# MMCSD8_MMC_CTLCFG_0FA00000h register map
Vendor: Texas Instruments
Registers are 16-bit, read-write, reset 0x0 unless marked. A register's access mark holds for its fields unless they carry their own. Offsets are as the file gives them; [hi:lo] are bit positions; {n}, {i} and the like mark numbered series.

## mmc_ctlcfg (part 2 of 4)
0x00 MMC_CTLCFG_SDMA_SYS_ADDR_LO — This register contains the Lower 16-bit of physical system memory address used for DMA transfers or the second argument for the Auto CMD23 in Host version 3.0 and as 32-bit Block Count in Version 4.10.
  [15:0] SDMA_ADDRESS — When Host Version 4 Enable is set to 0 in the Host Control 2 register,DMA uses this register as system address in only 32-bit addressing mode. Auto CMD23 cannot be used with SDMA. When Host Version 4 Enable is set to 1, SDMA uses ADMA System Address register [05Fh-058h] instead of using this register to sup- port both 32-bit and 64-bit addressing. This register is re-assigned to 32-bit Block Count and then SDMA may use Auto CMD23.[1] SDMA System Address [Host Version 4 Enable = 0] This register contains the system memory address for a SDMA transfer in 32-bit addressing mode. When the Host Controller stops a SDMA transfer, this register shall point to the system address of the next contiguous data position. It can be accessed only if no transaction is executing [i.e., after a transaction has stopped]. Reading this register during SDMA transfers may return an invalid value. The Host Driver shall initialize this register before starting a SDMA transaction. After SDMA has stopped, the next system address of the next contiguous data posi- tion can be read from this register. The SDMA transfer waits at the every boundary specified by the SDMA Buffer Boundary in the Block Size register. The Host Controller generates DMA Interrupt to request the Host Driver to update this register. The Host Driver sets the next system address of the next data position to this register. When the most upper byte of this register [003h] is written, the Host Controller restarts the SDMA transfer. When restarting SDMA by setting Continue Request in the Block Gap Control register, the Host Controller shall start at the next contiguous address stored here in the SDMA System Address register. ADMA does not use this register. [2] 32-bit Block Count [Host Version 4 Enable = 1] Host Controller Version 4.10 re-defines this register as 32-bit Block Count [Refer to Section 1.15 for more details about block count extension]. In version 4.00, this register may be used as 32-bit block count only for Auto CMD23 to set the argument of the CMD23 while executing Auto CMD23. The Host Controller would decrement the block count of this register every block transfer and data transfer stops when the count reaches zero. This register should be accessed only when no transaction is executing. Reading this register during data transfers may return invalid value. Reset Source: vbus_amod_g_rst_n
0x02 MMC_CTLCFG_SDMA_SYS_ADDR_HI — This register contains the Upper 16-bit of physical system memory address used for DMA transfers or the second argument for the Auto CMD23 in Host version 3.0 and as 32-bit Block Count in Version 4.10.
  [15:0] SDMA_ADDRESS — This register contains the Upper 16-bit of physical system memory address used for DMA transfers or the second argument for the Auto CMD23 in Host version 3.0 and as 32-bit Block Count in Version 4.10. Reset Source: vbus_amod_g_rst_n
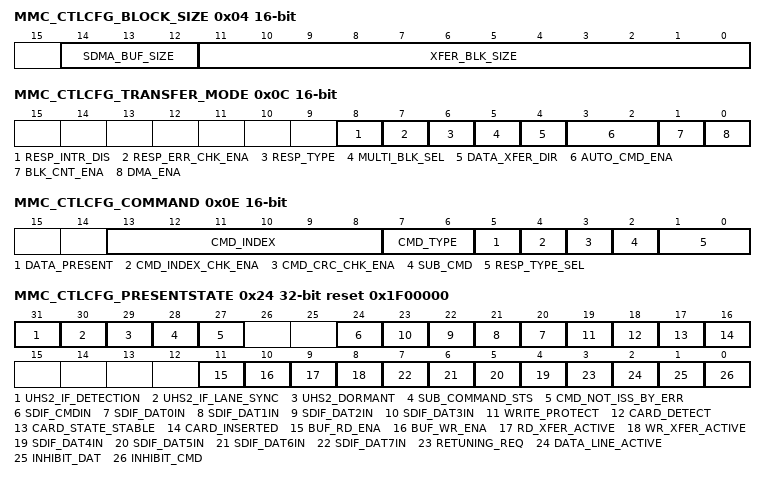
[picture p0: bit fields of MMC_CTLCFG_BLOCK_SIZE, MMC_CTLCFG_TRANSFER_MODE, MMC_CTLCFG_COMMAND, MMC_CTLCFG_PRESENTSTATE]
0x04 MMC_CTLCFG_BLOCK_SIZE — This register is used to configure the number of bytes in a data block
  [14:12] SDMA_BUF_SIZE — To perform long DMA transfer, System Address register shall be updated at every system boundary during DMA transfer. These bits specify the size of contiguous buffer in the system memory. The DMA transfer shall wait at the every boundary specified by these fields and the HC generates the DMA Interrupt to request the HD to update the System Address register.These bits shall support when the DMA Support in the Capabilities register is set to 1 and this function is active when the DMA Enable in the Transfer Mode register is set to 1. 0 4KB1 8KB2 16KB3 32KB4 64KB5 128KB6 256KB7 512KB
  [11:0] XFER_BLK_SIZE — This field specifies the block size for block data transfers for CMD17, CMD18, CMD24, CMD25 and CMD53. It can be accessed only if no transaction is executing [i.e after a transaction has stopped]. Read operations during transfer return an invalid value and write operations shall be ignored. 0 No data transfer1 1 Byte2 2 Bytes512 512 Bytes2048 2048 Bytes
0x06 MMC_CTLCFG_BLOCK_COUNT — This register is used to configure the number of data blocks
  [15:0] XFER_BLK_CNT — Host Controller Version 4.10 extends block count to 32-bit [Refer to Section 1.15].Selection of either 16-bit Block Count register or 32-bit Block Count register is defined as follows: [1] If Host Version 4 Enable in the Host Control 2 register is set to 0 or 16-bit Block Count register is set to non-zero, 16-bit Block Count register is selected [2] If Host Version 4 Enable is set to 1 and 16-bit Block Count register is set to zero, 32-bit Block Count register is selected.Use of 16-bit/32-bit Block Count register is enabled when Block Count Enable in the Transfer Mode register is set to 1 and is valid only for multiple block transfers. The Host Driver shall set this register to a value between 1 and the maximum block count.The Host Controller decrements the block count after each block transfer and stops when the count reaches zero. Setting the block count to 0 results in no data blocks is transferred.This register should be accessed only when no transaction is executing [i.e., after transactions arestopped]. During data transfer,read operations on this register may return an invalid value andwrite operations are ignored. 0 Stop count1 1 block2 2 blocks3 3 blocks65535 65535 blocks
0x08 MMC_CTLCFG_ARGUMENT1_LO — This register contains Lower bits of SD Command Argument
  [15:0] CMD_ARG1 — The SD Command Argument is specified as bit23-8 of Command-Format. Reset Source: vbus_amod_g_rst_n
0x0A MMC_CTLCFG_ARGUMENT1_HI — This register contains higher bits of SD Command Argument
  [15:0] CMD_ARG1 — The SD Command Argument is specified as bit39-24 of Command-Format. Reset Source: vbus_amod_g_rst_n
0x0C MMC_CTLCFG_TRANSFER_MODE — This register is used to control the operations of data transfers
  [8] RESP_INTR_DIS — Host Controller Version 4.00 supports response error check function to avoid overhead of response error check by Host Driver. Only R1 or R5 can be checked. If Host Driver checks response error,setsthis bit to 0 and waits Command Complete Interrupt and then checks the response register. If Host Controller checks response error, sets this bit to 1 and sets Response Error Check Enable to 1. Command Complete Interrupt is disabled by this bit regardless of Command Complete Signal Enable. 0 Enable Response Interrupt1 Disable Response Interrupt
  [7] RESP_ERR_CHK_ENA — Host Controller Version 4.00 supports response error check function to avoid overhead of response error check by Host Driver. Only R1 or R5 can be checked.If Host Driver checks response error, this bit is set to 0 and Response Interrupt Disable is set to 0.If Host Controller checks response error, sets this bit to 1 and sets Response Interrupt Disable to 1. Response Type R1 / R5 selects either R1 or R5 response type. If an error is detected, Response Error Interrupt is generated in the Response Error Interrupt Status register. 0 Disable Response Error Check1 Enable Response Error Check
  [6] RESP_TYPE — When response error check is enabled, this bit selects either R1 or R5 response types. Two types of response checks are supported: R1 for memory and R5 for SDIO. Error Statuses Checked in R1 .Bit31 OUT_OF_RANGE .Bit30 ADDRESS_ERROR .Bit29 BLOCK_LEN_ERROR .Bit26 WP_VIOLATION .Bit25 CARD_IS_LOCKED .Bit23 COM_CRC_ERROR .Bit21 CARD_ECC_FAILED .Bit20 CC_ERROR .Bit19 ERROR Response Flags Checked in R5 .Bit07 COM_CRC_ERROR .Bit03 ERROR .Bit01 FUNCTION_NUMBER .Bit00 OUT_OF_RANGE 0 Memory1 SDIO
  [5] MULTI_BLK_SEL — This bit enables multiple block data transfers. 0 Single Block transfer1 Multiple Block transfer
  [4] DATA_XFER_DIR — This bit defines the direction of data transfers. 0 Write from Host to Card1 Read from Card to Host
  [3:2] AUTO_CMD_ENA — There are three methods to stop Multiple-block read and write operation. [1] Auto CMD12 Enable: Multiple-block read and write commands for memory require CMD12 to stop the operation. When this field is set to 01b, the Host Controller issues CMD12 automatically when last block transfer is completed. Auto CMD12 error is indicated to the Auto CMD Error Status register. The Host Driver shall not set this bit if the command does not require CMD12. When Host Version 4 Enable =0, CMD12 is issued when 16-bit Block Count is expired. When Host Version 4 Enable =1, CMD12 is issued when 16-bit Block Count or 32-bit Block Count is expired. [2] Auto CMD23 Enable: When this bit field is set to 10b, the Host Controller issues a CMD23 automatically before issuing a command specified in the Command register. The Host Controller Version 3.00 and later shall support this function. The following conditions are required to use the Auto CMD23. The following conditions are required to use the Auto CMD23. Auto CMD23 Supported [Host Controller Version is 3.00 or later]. A memory card that supports CMD23 [SCR[33]=1]. If DMA is used, it shall be ADMA. Only when CMD18 or CMD25 is issued. Auto CMD23 can be used with or without ADMA. By Writing the Command register, the Host Controller issues a CMD23 first and then issues a command specified by the Command Index in Com-mand register. If response errors of CMD23 are detected, the second command is not issued. A CMD23 error is indicated in the Auto CMD Error Status register.32-bit block count value for CMD23 is set to 32-bit Block Count [SDMA System Address] register. [3] Auto CMD Auto Select [Version 4.10] As CMD23 is optional for SD memory card except UHS 104 card, if card supports CMD23, Auto CMD 23 should be used instead of Auto CMD12. Host Controller Version 4.10 defines this Auto CMD Auto Select mode. Selection of Auto CMD depends on setting of CMD23 Enable in the Host Control 2 register which indicates whether card supports CMD23. If CMD23 Enable =1, Auto CMD23 is used and if CMD23 Enable =0, Auto CMD12 is used. In case of Version 4.10 or later, use of Auto CMD Auto Select is recommended rather than use of Auto CMD12 Enable or Auto CMD23 Enable. 0 Auto CMD Disable1 Auto CMD12 Enable2 Auto CMD23 Enable3 Auto CMD Auto Select
  [1] BLK_CNT_ENA — This bit is used to enable the Block count register, which is only relevant for multiple block transfers. When this bit is 0, the Block Count register is disabled, which is useful in executing an infinite transfer. 0 Disable Block count1 Enable Block count
  [0] DMA_ENA — DMA can be enabled only if DMA Support bit in the Capabilities register is set. If this bit is set to 1, a DMA operation shall begin when the HD writes to the upper byte of Command register [00Fh]. 0 DMA mode is Disabled1 DMA mode is Enabled
0x0E MMC_CTLCFG_COMMAND — This register is used to program the Command for host controller
  [13:8] CMD_INDEX — This bit shall be set to the command number [CMD0-63, ACMD0-63]. Reset Source: vbus_amod_g_rst_n
  [7:6] CMD_TYPE — There are three types of special commands. Suspend, Resume andAbort. These bits shall bet set to 00b for all other commands. Suspend Command:If the Suspend command succeeds, the HC shall assume the SD Bus has been released and that it is possible to issue the next command which uses the DAT line. The HC shall de-assert Read Wait for read transactions and stop checking busy for write transactions. The Interrupt cycle shall start, in 4-bit mode. If the Suspend command fails, the HC shall maintain its current state. and the HD shall restart the transfer by setting Continue Request in the Block Gap Control Register. Resume Command:The HD re-starts the data transfer by restoring the registers in the range of 000-00Dh. The HC shall check for busy before starting write transfers. Abort Command:If this command is set when exe- cuting a read transfer, the HC shall stop reads to the buffer. If this command is set when executing a writetransfer, the HC shall stop driving the DAT line. After issuing the Abort command, the HD should issue a software reset. 0 Normal1 Suspend2 Resume3 Abort
  [5] DATA_PRESENT — This bit is set to 1 to indicate that data is present and shall be transferred using the DAT line. If is set to 0 for the following: 1. Commands using only CMD line [ex. CMD52]. 2. Commands with no data transferbut using busy signal on DAT[0]line [R1b or R5b ex. CMD38]. 3. Resume Command. 0 Data not Present1 Data present
  [4] CMD_INDEX_CHK_ENA — If this bit is set to 1, the HC shall check the index field in the response to see if it has the same value as the command index. If it is not, it is reported as a Command Index Error. If this bit is set to 0, the Index field is not checked. 0 Disable Command Index Check1 Enable Command Index Check
  [3] CMD_CRC_CHK_ENA — If this bit is set to 1, the HC shall check the CRC field in the response. If an error is detected, it is reported as a Command CRC Error. If this bit is set to 0, the CRC field is not checked. 0 Disable Command CRC Check1 Enable Command CRC Check
  [2] SUB_CMD — This bit is added from Version 4.10 to distinguish a main command or sub command [Refer to Section 1.17]. When issuing a main com-mand, this bit is set to 0 and when issuing a sub command, this bit is set to 1. Setting of this bit is checked by Sub Command Status in the Present State register.Host Driver manages whether main or sub command. Host Controller does not refer to this bit to issue a command. 0 Main Command1 Sub Command
  [1:0] RESP_TYPE_SEL — Response Type Select. 0 No Response1 Response length 1362 Response length 483 Response length 48 check Busy after response
0x10 MMC_CTLCFG_RESPONSE_j ro — This register is used to store responses from SD Cards
  [15:0] CMD_RESP — R[] refers to a bit range within the response data as transmitted on the SD Bus, REP[] refers to a bit range within the Response register. Reset Source: vbus_amod_g_rst_n
0x20 MMC_CTLCFG_DATA_PORT 32-bit — This register is used to access internal buffer
  [31:0] BUF_RD_DATA — The Host Controller Buffer can be accessed through this 32-bit Data Port Register. Reset Source: vbus_amod_g_rst_n
0x24 MMC_CTLCFG_PRESENTSTATE 32-bit ro reset 0x1F00000 — The Host Driver can get status of the Host Controller from this 32-bit read-only register
  [31] UHS2_IF_DETECTION — This status indicates whether a card supports UHS-II IF. This status is enabled by setting UHS-II Interface Enable to 1 in the Host Control 2 regis-ter. UHS-II interface initialization is activated by setting SD Clock Enable in the Clock Control reg-ister. Host Controller drives STB.L on D0 lanefrom EIDL state and waits for receiving STB.L on D1 lane. This bit is set to 1 if STB.L is detected on D1 lane. Host Controller shall compensate latency from setting SD Clock Enable to output STB.L on D0 lane when Reading this status [Refer to Figure 3-35 about details of this method]. This bit may be read any time after setting SD Clock Enable for faster UHS-II IF detection but Host Driver shall check this status at least 200us period from set- ting SD Clock Enable until detecting UHS-II IF. After UHS-II IF is detected, this bit is cleared by when EIDL is detected on D0 lane, UHS-II Inter-face Enable is set to 0 or Host full reset is exe-cuted. '0' UHS-II IF is not detected '1' UHS-II IF is detected Reset Source: vbus_amod_g_rst_n
  [30] UHS2_IF_LANE_SYNC — This status indicates whether lane is synchronized in UHS-II mode. This status is enabled by setting UHS-II Interface Enable to 1 in the Host Control 2 register. On detecting UHS-II Interface [D31=1], Host Controller provides SYN LSS on D0 lane and waits for receiving SYN LSS on D1 lane. If SYN LSS is detected on D1 lane, Host Controller pro-vides LIDL LSS on D0 lane and waits for receiving LIDL LSS on D1 lane.In case of Version 4.00, this bit indicates comple-tion of Device PHY Initialization by detecting LIDL LSS on D1 lane.From Version 4.10, Host Controller may imple-ment a specific PHY verification method and PHYInitialization Failure can be indicated by keeping this bit to 0 even LIDL LSS is detected on D1 lane.Host Driver detects PHY Initialization Failure by timeout.This bit is cleared by when D0 lane is set to EIDL,UHS-II Interface Enable is set to 0 or executes Host full reset. 0 UHS-II PHY is not initialized1 UHS-II PHY is initialized
  [29] UHS2_DORMANT — This status indicates whether UHS-II Ianes enterDormant state. This function is enabled by setting UHS-II Interface Enable to 1 in the Host Control 2 register. On issuing GO_DORMAT_STATE com-mand, Go Dormant Command [111b]; is set to Command type in the UHS-II Command register.This command type acts as a trigger to enterlanes into dormant state. Host Controller provides STB.H and EIDL on D0 lane and waits for receiv-ing STB.H and EIDL on D1 lane. This bit is set to 1 after the time of T_DMT_ENTRY [750 RCLK cycle] or more from detecting EIDL on D1 lane. RCLK may be stopped in dormant state, by setting SD Clock Enable to 0 in the Clock Control register while In Dormant State bit is set to 1. On WritingClock Control register with setting SD Clock Enable to 1, Host Controller wakes lanes to exit Dormant State and In Dormant State is set to 0. In case of the card enters Hibernate Mode [RCLK is stopped], Host Driver may turn off VDD1 by clearing SD Bus Power for VDD1 bit in the Power Control register. Host Controller shall turn off VDD1 after stopping RCLK. This bit is cleared by when Host Controller drives STB.L on D0 lane, UHS-II Interface Enable is set to 0 or executesHost full reset. 0 Not in DORMANT state1 In DORMANT state
  [28] SUB_COMMAND_STS — The Command register and Response register are commonly used for main command and sub command. This status is used to distinguish which response error statuses, main command or sub command, indicated in the Error Interrupt Status register or in the UHS-II Error Interrupt Status register. Refer to Section 1.17 about details of response error statuses. Just before Reading of this register, the Sub Command Flag of the Command register or the UHS-II Command register is copied to this status. This status is effective not only when Response Error interrupt is generated but also when data error interrupt is generated with Command Not Issued by Error [D27 of this register] or Auto CMD Error interrupt is generated with Command Not Issued by Error by Auto CMD12 in the Auto CMD Error Status register. 1 - Sub Command Status 0 - Main Command Status Reset Source: vbus_amod_g_rst_n
  [27] CMD_NOT_ISS_BY_ERR — Setting of this status indicates that a command cannot be issued due to an error except Auto CMD12 error. [Equivalent error status by Auto CMD12 error is defined as Command Not Issued By Auto CMD12 Error in the Auto CMD Error Status register.] This status is set to 1 when Host Controller cannot issue a command after setting Command register or UHS-II Command register.Refer to Section 3.10 about 2L-HD error case inUHS-II mode.Sub Command Status [D28] indicates which command is not issued [main or sub]. 1 - Command cannot be issued 0 - No error for issuing a command Reset Source: vbus_amod_g_rst_n
  [24] SDIF_CMDIN — This status is used to check DAT line level to recover from errors, and for debugging. Reset Source: vbus_amod_g_rst_n
  [n+20] SDIF_DAT{n}IN (n=0..3) — This status is used to check DAT line level to recover from errors, and for debugging. This is especially useful in detecting the busy signal level from DAT[{n}]. Reset Source: vbus_amod_g_rst_n
  [19] WRITE_PROTECT — The Write Protect Switch is supported for memory and combo cards.This bit reflects the SDWP# pin. 0 Write protected (SDWP# = 1)1 Write enabled (SDWP# = 0)
  [18] CARD_DETECT — This bit reflects the inverse value of the SDCD# pin. '0' No Card present [SDCD# = 1] '1' Card present [SDCD# = 0] Reset Source: vbus_amod_g_rst_n
  [17] CARD_STATE_STABLE — This bit is used for testing. If it is 0, the Card Detect Pin Level is not stable. If this bit is set to 1,it means the Card Detect Pin Level is stable. The Software Reset For All in the Software Reset Register shall not affect this bit. '0' Reset of Debouncing '1' No Card or Inserted Reset Source: vbus_amod_g_rst_n
  [16] CARD_INSERTED — This bit indicates whether a card has been inserted. Changing from 0 to 1 generates a Card Insertion interrupt in the Normal Interrupt Status register and changing from 1 to 0 generates a Card Removal Interrupt in the Normal Interrupt Status register. The Software Reset For All in the Software Reset register shall not affect this bit.If a Card is removed while its power is on and its clock is oscillating, the HC shall clear SD Bus Power in the Power Control register and SD Clock Enable in the Clock control register. In addition the HD should clear the HC by the Software Reset For All in Software register. The card detect is active regardless of the SD Bus Power. '0' Reset or Debouncing or No Card '1' Card Inserted Reset Source: vbus_amod_g_rst_n
  [11] BUF_RD_ENA — This status is used for non-DMA read transfers.This read only flag indicates that valid data exists in the host side buffer status. If this bit is 1, readable data exists in the buffer. A change of this bit from 1 to 0 occurs when all the block data is read from the buffer. A change of this bit from 0 to 1 occurs when all the block data is ready in the buffer and generates the Buffer Read Ready Interrupt. 0 Read Disable1 Read Enable
  [10] BUF_WR_ENA — This status is used for non-DMA write transfers.This read only flag indicates if space is available for write data. If this bit is 1, data can be written to the buffer. A change of this bit from 1 to 0 occurs when all the block data is written to the buffer. A change of this bit from 0 to 1 occurs when top of block data can be written to the buffer and generates the Buffer Write Ready Interrupt. 0 Write Disable1 Write Enable
  [9] RD_XFER_ACTIVE — This status is used for detecting completion of a read transfer. This bit is set to 1 for either of the following conditions: After the end bit of the read command. When Writing a 1 to continue Request in the Block Gap Control register to restart a read transfer. This bit is cleared to 0 for either of the following conditions: When the last data block as specified by block length is transferred to the system. When all valid data blocks have been transferred to the system and no current block transfers are being sent as a result of the Stop At Block Gap Request set to 1. A transfer complete interrupt is generated when this bit changes to 0. '0' No valid data '1' Transferring data 0 No valid data1 Transferring data
  [8] WR_XFER_ACTIVE — This status indicates a write transfer is active. If this bit is 0, it means no valid write data exists in the HC. This bit is set in either of the following cases: After the end bit of the write command. When Writing a 1 to Continue Request in the Block Gap Control register to restart a write transfer. This bit is cleared in either of the following cases: After getting the CRC status of the last data block as specified by the transfer count [Single or Multiple] After getting a CRC status of any block where data transmission is about to be stopped by a Stop At Block Gap Request.During a write transaction, a Block Gap Event interrupt is generated when this bit is changed to 0, as a result of the Stop At Block Gap Request being set. This status is useful for the HD in determining when to issue commands during write busy. 0 No valid data1 Transferring data
  [n] SDIF_DAT{n}IN (n=4..7) — This status is used to check DAT line level to recover from errors, and for debugging. Reset Source: vbus_amod_g_rst_n
  [3] RETUNING_REQ — Host Controller may request Host Driver to execute re-tuning sequence by setting this bit when the data window is shifted by temperature drift and a tuned sampling point does not have a good margin to receive correct data.This bit is cleared when a command is issued with setting Execute Tuning in the Host Control 2 register. Changing of this bit from 0 to 1 generates Re-Tuning Event. Refer to Normal Interrupt registers for more detail. This bit isn't set to 1 if Sampling Clock Select in the Host Control 2 register is set to 0 [using fixed sampling clock]. 0 Fixed or well tuned sampling clock1 Sampling clock needs re-tuning
  [2] DATA_LINE_ACTIVE — This bit indicates whether one of the DAT line on SD bus is in use. 0 DAT line inactive1 DAT line active
  [1] INHIBIT_DAT — This status bit is generated if either the DAT Line Active or the Read transfer Active is set to 1. If this bit is 0, it indicates the HC can issue the next SD command. Commands with busy signal belong to Command Inhibit [DAT] [ex. R1b, R5b type].Changing from 1 to 0 generates a Transfer Complete interrupt in the Normal interrupt status register.Note: The SD Host Driver can save registers in the range of 000-00Dh for a suspend transaction after this bit has changed from 1 to 0. '0' Can issue command which uses the DAT line '1' Cannot issue command which uses the DATline Reset Source: vbus_amod_g_rst_n
  [0] INHIBIT_CMD — SD ModeIf this bit is 0, it indicates the CMD line is not in use and the HC can issue a SD command using the CMD line. This bit is set immediately after the Command register [00Fh] is written. This bit is cleared when the command response is received. Even if the Command Inhibit [DAT] is set to 1, Commands using only the CMD line can be issued if this bit is 0. Changing from 1 to 0 gener- ates a Command complete interrupt in the Normal Interrupt Status register. If the HC cannot issuethe command because of a command conflict error or because of Command Not Issued By Auto CMD12 Error, this bit shall remain 1 and the Com- mand Complete is not set. Status issuing Auto CMD12 is not read from this bit.Auto CMD12 and Auto CMD23 consist of two responses. In this case, this bit is not cleared by the response of CMD12 or CMD23 but cleared by the response of a read/write command. Status issuing Auto CMD12 is not read from this bit. So ifa command is issued during Auto CMD12 opera- tion, Host Controller shall manage to issue two commands: CMD12 and a command set by Com-mand register. UHS-II ModeThis bit is 0 means that a command packet can be issued by the Host Controller. While this bit is set to 1, which means the Host Controller is not ready to issue a next command, Host Driver shall not write the registers from UHS-II BlockSize [Offset 080h] to the UHS-II Command [Offset 09Eh]. Changing from 1 to 0 generates a Command Complete Interrupt in the Normal Interrupt Status-register. 1- Host Controller is not ready to issue a com-mand 0 - Host Controller is ready to issue a commandVersion 4.10 adds a new control to prevent error statuses from overWriting by receipt of a next com-mand. This status keeps indicating 1 while any of response error statuses is set to 1 [as described in Section 1.17], Command Not Issued by Error in this register is set to 1 or Command Not Issued by Auto CMD12 Error in the Auto CMD Error Status register is set to 1. Software Reset For CMD Lineis used to clear the error statuses above and this status. Reset Source: vbus_amod_g_rst_n
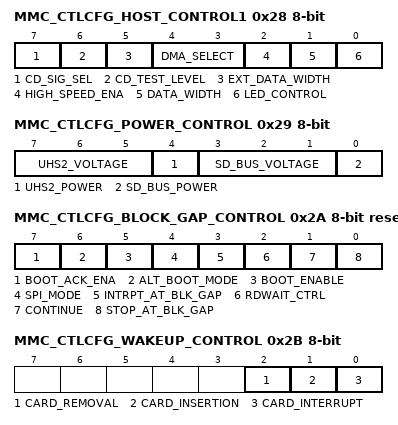
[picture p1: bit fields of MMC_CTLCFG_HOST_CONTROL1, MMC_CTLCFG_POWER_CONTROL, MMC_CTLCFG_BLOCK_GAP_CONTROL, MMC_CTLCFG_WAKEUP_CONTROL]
0x28 MMC_CTLCFG_HOST_CONTROL1 8-bit — This register is used to program DMA modes, LED Control, Data Transfer Width, High Speed Enable, Card detect test level and signal selection
  [7] CD_SIG_SEL — This bit selects source for card detection. '0' SDCD# is selected [for normal use] '1' The card detect test level is selected Reset Source: vbus_amod_g_rst_n
  [6] CD_TEST_LEVEL — This bit is enabled while the Card Detect Signal Selection is set to 1 and it indicates card inserted or not. Generates [card ins or card removal] interrupt when the normal int sts enable bit is set. '0' No Card '1' Card Inserted Reset Source: vbus_amod_g_rst_n
  [5] EXT_DATA_WIDTH — This bit controls 8-bit bus width mode for embedded device. Support of this function is indicated in 8-bit Support for Embedded Device in the Capabilities register. If a device supports 8-bit bus mode, this bit may be set to 1. If this bit is 0, bus width is controlled by Data Transfer Width in the Host Control 1 register.This bit is not effective when multiple devices are installed on a bus slot [Slot Type is set to 10b in the Capabilities register]. In this case, each device bus width is controlled by Bus Width Preset field in the Shared Bus register. 0 Bus width is selected by data transfer width1 8-bit bus width
  [4:3] DMA_SELECT — This field is used to select DMA type. The Host Driver shall check support of DMA modes by referring the Capabilities register. Selected DMA is enabled by DMA Enable of the Transfer Mode register in SD mode and DMA Enable of UHS-II Transfer Mode register in UHS-II mode. [1] Up to Version 3.00 When Host Version 4 Enable is set to 0, setting of this field is compatible to Host Controller Version 3.00.SDMA is initiated by Writing to the Command register when this field is set to 00b and the SDMA System Address regis-ter [32-bit] is used. SDMA does not support 64-bit address-ing.ADMA2 is initiated by Writing to the Command register when this field is set to 10b or 11b. Lower 32-bit of the ADMA Sys-tem Address register is used when this field is set to 10b and 64-bit of the ADMA System Address register is used when this field is set to 11b. Support of 64-bit System Addressingis indicated by 64-bit System Address Support for V3 in the Capabilities register. 64-bit AMDA2 uses 96-bit Descriptor. 00 - SDMA is selected 01 - 32-bit Address ADMA1 is selected 10 -32-bit Address ADMA2 is selected 11 - 64-bit Address ADMA2 is selected [Optional] [2] Version 4.00 or later When Host Version 4 Enable is set to 1, setting of this field is changed as follows. SDMA is initiated by Host Driver writes to the Command reg-ister when this field is set to 00b.ADMA2 is initiated by Host Driver writes to the Command register when this field is set to 10b or 11b and by ADMA3 sets to the ADMA System Address register when this field is set to 11b. ADMA3 is initiated by Host Driver writes to the ADMA3 IDAddress register when this field is set to 11b. 00 - SDMA is selected 01 - Not Used [New assignment is not allowed] 10 - ADMA2 is selected [AMDA3 is not supported or dis-abled] 11 - ADMA2 or ADMA3 is selected Support of 64-bit DMA and 128-bit Descriptor is indicated by 64-bit System Address Support for V4 in the Capabilities register. If the support bit is set to 1, all supported DMAs[depends on Support, ADMA2 Support and ADMA3 Sup-port] shall support 64-bit addressing. 64-bit Addressing in the Host Controller 2 register selects either 32-bit or 64-bit system addressing of DMAs. Reset Source: vbus_amod_g_rst_n
  [2] HIGH_SPEED_ENA — This bit is optional. Before setting this bit, the HD shall check the High Speed Support in the capabilities register. If this bit is set to 0 [default], the HC outputs CMD line and DAT lines at the falling edge of the SD clock [up to 25 MHz/20MHz for MMC]. If this bit is set to 1, the HC outputs CMD line and DAT lines at the rising edge of the SD clock [up to 50 MHz for SD/52MHz for MMC]/ 208Mhz [for SD3.0]If Preset Value Enable in the Host Control 2 register is set to 1, Host Driver needs to reset SD Clock Enable before changing this field to avoid generating clock glitches. After setting this field, the Host Driver sets SD Clock Enable again. This bit is not effective in UHS-II mode. 0 Normal Speed Mode1 High Speed Mode
  [1] DATA_WIDTH — This bit selects the data width of the HC. The HD shall select it to match the data width of the SD card. This bit is not effective in UHS-II mode. 0 1 bit mode1 4 bit mode
  [0] LED_CONTROL — This bit is used to caution the user not to remove the card while the SD card is being accessed. If the software is going to issue multiple SD commands, this bit can be set during all transactions. It is not necessary to change for each transaction. 0 LED off1 LED on
0x29 MMC_CTLCFG_POWER_CONTROL 8-bit — This register is used to program the SD Bus power and voltage level
  [7:5] UHS2_VOLTAGE — This field determines supply voltage range to VDD2. This field can be set to 101b if 1.8V VDD2 Support in the Capabilities register is set to 1. '000' VDD2 Not supported '001'- '011' Reserved '100' Reserved for 1.2V '101' 1.8V '110' Not Used '111' Not Used Reset Source: vbus_amod_g_rst_n
  [4] UHS2_POWER — Setting this bit enables providing VDD2. '0' Power Off '1' Power On 0 Power Off1 Power On
  [3:1] SD_BUS_VOLTAGE — By setting these bits, the HD selects the voltage level for the SD card. Before setting this register, the HD shall check the voltage support bits in the capabilities register. If an unsupported voltage is selected, the Host System shall not supply SD bus voltage. '000'- '100' Reserved '101' 1.8V '110' 3.0V '111' 3.3V 0 Reserved5 1.8V6 3.0V7 3.3V
  [0] SD_BUS_POWER — Before setting this bit, the SD host driver shall set SD Bus Voltage Select. If the HC detects the No Card State, this bit shall be cleared. If this bit is cleared, the Host Control-ler should immediately stop driving CMD and DAT[3:0] [tri-state], and drive SDCLK to low level [Refer to Section 2.2.14]. If card is connectedto Host Controller, Host Controller shall set these lines to low before stopping to supply VDD1.In UHS-II mode, before clearing this bit, Host Driver shall clear SD Clock Enable and before stopping to sup-ply VDD1, Host Controller shall setDAT[2] to low if DAT[2] is used as out-of band interrupt. 0 Power Off1 Power On
0x2A MMC_CTLCFG_BLOCK_GAP_CONTROL 8-bit reset 0x80 — This register is used to program the block gap request, read wait control and interrupt at block gap
  [7] BOOT_ACK_ENA — To check for the boot acknowledge in boot operation. 0 Will not wait for boot ack from eMMC card1 Wait for boot ack from eMMC card
  [6] ALT_BOOT_MODE — To start boot code access in alternative mode. 0 To stop alternative boot code access1 To start alternative boot code access
  [5] BOOT_ENABLE — To start boot code access. 0 To stop boot code access1 To start boot code access
  [4] SPI_MODE — SPI mode enable bit. 0 SD Mode1 SPI Mode
  [3] INTRPT_AT_BLK_GAP — This bit is valid only in 4-bit mode of the SDIO card and selects a sample point in the interrupt cycle. Setting to 1 enables interrupt detection at the block gap for a multiple block transfer. If the SD card cannot signal an interrupt during a multiple block transfer, this bit should be set to 0. When the HD detects an SD card insertion, it shall set this bit according to the CCCR of the SDIO card. Reset Source: vbus_amod_g_rst_n
  [2] RDWAIT_CTRL — The read wait function is optional for SDIO cards. If the card supports read wait, set this bit to enable use of the read wait protocol to stop read data using DAT[2] line. Otherwise the HC has to stop the SD clock to hold read data, which restricts commands generation. When the HD detects an SD card insertion, it shall set this bit according to the CCCR of the SDIO card. If the card does not support read wait, this bit shall never be set to 1 otherwise DAT line conflict may occur. If this bit is set to 0, Suspend / Resume cannot be supported. In UHS-II mode, Read Wait is disabled and DAT[2] line is used for Interrupt Signal from UHS-II Card. 0 Disable Read-Wait Control1 Enable Read-Wait Control
  [1] CONTINUE — This bit is used to restart a transaction which was stopped using the Stop At Block Gap Request. To cancel stop at the block gap, set Stop At block Gap Request to 0 and set this bit to restart the transfer.The Host Controller automatically clears this bit when the transaction re-starts.If Stop At Block Gap Request is set to 1, any write to this bit is ignored.In SD mode, this bit is cleared in either of the following cases:[1] In the case of a read transaction, the DAT Line Active changes from 0 to 1 as a read transaction restarts.[2] In the case of a write transaction, the Write transfer active changes from 0 to 1 as the write transaction restarts.Therefore it is not necessary for Host driver to set this bit to 0. If Stop At Block Gap Request is set to 1, any write to this bit is ignored. '0' Ignore '1' Restart 0 Ignore1 Restart
  [0] STOP_AT_BLK_GAP — This bit is used to stop executing a transaction at the next block gap for non- DMA,SDMA and ADMA transfers. Until the transfer complete is set to 1, indicating a transfer completion the HD shall leave this bit set to 1. Clearing both the Stop At Block Gap Request and Continue Request shall not cause the transaction to restart. Read Wait is used to stop the read transaction at the block gap. The HC shall honour Stop At Block Gap Request for write transfers, but for read transfers it requires that the SD card support Read Wait. Therefore the HD shall not set this bit during read transfers unless the SD card supports Read Wait and has set Read Wait Control to 1. In case of write transfers in which the HD writes data to the Buffer Data Port register, the HD shall set this bit after all block data is written. If this bit is set to 1, the HD shall not write data to Buffer data port register. This bit affects Read Transfer Active, Write Transfer Active, DAT line active and Command Inhibit [DAT] in the Present State register. In case of UHS-II, a transaction can be stopped at the boundary of DATA Burst [Flow Control basis]. Host Control-ler waits for sending Flow Control MSG until Continue Request is set to 1. '0' Transfer '1' Stop 0 Transfer1 Stop
0x2B MMC_CTLCFG_WAKEUP_CONTROL 8-bit — This register is used to program the wakeup functionality
  [2] CARD_REMOVAL — This bit enables wakeup event via Card removal assertion in the Normal Interrupt Status register.FN_WUS [Wake up Support] in CIS does not affect this bit. 0 Disable wakeup event1 Enable wakeup event via Card removal
  [1] CARD_INSERTION — This bit enables wakeup event via Card Insertion assertion in the Normal Interrupt Status register.FN_WUS [Wake up Support] in CIS does not affect this bit. 0 Disable wakeup event1 Enable wakeup event via Card Insertion
  [0] CARD_INTERRUPT — This bit enables wakeup event via Card Interrupt assertion in the Normal Interrupt Status register.This bit can be set to 1 if FN_WUS [Wake Up Support] in CIS is set to 1. 0 Disable wakeup event1 Enable wakeup event via Card Interrupt
